# STM32C591 register map
File version: 2.1.0
CPU: CM33 r0p4, little endian, MPU, FPU, 4 interrupt priority bits
Registers are 32-bit, read-write, reset 0x0 unless marked. A register's access mark holds for its fields unless they carry their own. Offsets are from the block's base; [hi:lo] are bit positions; {n}, {i} and the like mark numbered series; 'fields as' and 'values as' point back to an identical list.

## RAMCFG — RAMCFG register block
Base 0x40026000
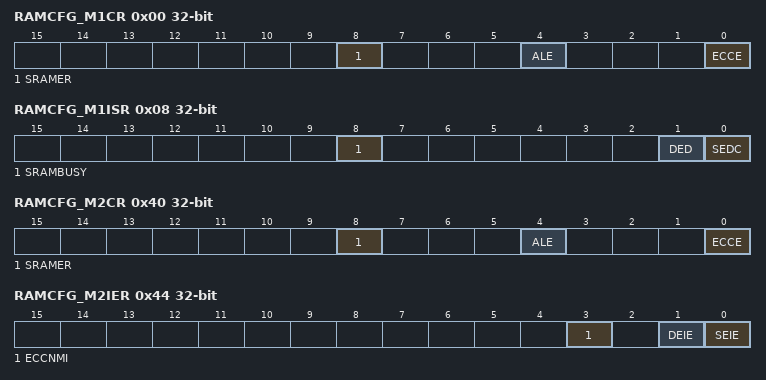
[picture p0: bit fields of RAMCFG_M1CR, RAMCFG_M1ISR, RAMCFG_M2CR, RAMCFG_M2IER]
0x00 RAMCFG_M1CR (reset mask 0xFFFFFFF0) — RAMCFG memory 1 control register
  [8] SRAMER — SRAM erase
    0=No erase operation ongoing; 1=Erase operation ongoing
  [4] ALE — Address latch enable
    0=Failing address not stored in the SRAMx ECC single/double error address registers; 1=Failing address stored in the SRAMx ECC single/double error address registers
  [0] ECCE — ECC enable.
    0=ECC disabled; 1=ECC enabled
0x08 RAMCFG_M1ISR ro — RAMCFG memory 1 interrupt status register
  [8] SRAMBUSY — SRAM busy with erase operation
    0=No erase operation ongoing; 1=Erase operation ongoing
  [1] DED — ECC double error detected
    0=No double error; 1=Double error detected
  [0] SEDC — ECC single error detected and corrected
    0=No single error; 1=Single error detected and corrected
0x28 RAMCFG_M1ERKEYR wo — RAMCFG memory 1 erase key register
  [7:0] ERASEKEY — Erase write protection key
0x40 RAMCFG_M2CR (reset mask 0xFFFFFFF0) — RAMCFG memory 2 control register
  fields as RAMCFG_M1CR
0x44 RAMCFG_M2IER — RAMCFG memory 2 interrupt enable register
  [3] ECCNMI — Double error NMI
    0=NMI not generated in case of ECC double error; 1=NMI generated in case of ECC double error
  [1] DEIE — ECC double error interrupt enable
    0=Double error interrupt disabled; 1=Double error interrupt enabled
  [0] SEIE — ECC single error interrupt enable
    0=Single error interrupt disabled; 1=Single error interrupt enabled
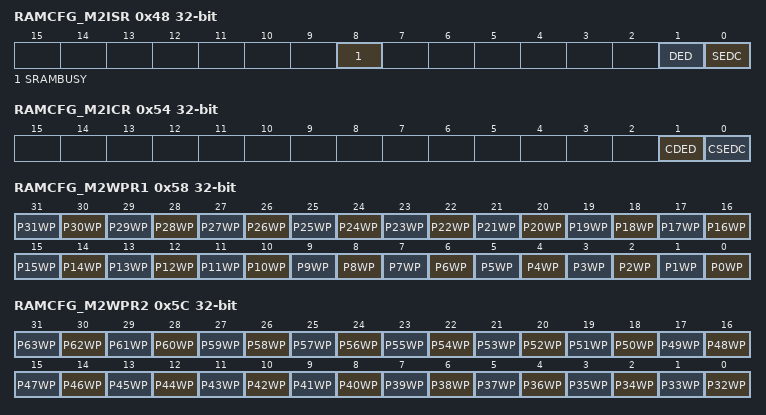
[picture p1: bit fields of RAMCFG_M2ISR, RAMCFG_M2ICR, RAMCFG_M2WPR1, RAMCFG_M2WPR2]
0x48 RAMCFG_M2ISR ro — RAMCFG memory 2 interrupt status register
  fields as RAMCFG_M1ISR
0x4C RAMCFG_M2SEAR ro — RAMCFG memory 2 ECC single error address register
  [31:0] ESEA — ECC single error address
0x50 RAMCFG_M2DEAR ro — RAMCFG memory 2 ECC double error address register
  [31:0] EDEA — ECC double error address
0x54 RAMCFG_M2ICR — RAMCFG memory 2 interrupt clear register
  [1] CDED — Clear ECC double error detected
  [0] CSEDC — Clear ECC single error detected and corrected
0x58 RAMCFG_M2WPR1 — RAMCFG memory 2 write protection register 1
  [all] fields
    0=Write protection of SRAM2 1-Kbyte page y is disabled; 1=Write protection of SRAM2 1-Kbyte page y is enabled
  [n] P{n}WP (n=0..31) — SRAM2 1-Kbyte page y write protection
0x5C RAMCFG_M2WPR2 — RAMCFG memory 2 write protection register 2
  [all] fields
    values as the fields of RAMCFG_M2WPR1
  [n-32] P{n}WP (n=32..63) — SRAM2 1-Kbyte page y write protection
0x64 RAMCFG_M2ECCKEYR wo — RAMCFG memory 2ECC key register
  [7:0] ECCKEY — ECC write protection key
0x68 RAMCFG_M2ERKEYR wo — RAMCFG memory 2 erase key register
  [7:0] ERASEKEY — Erase write protection key
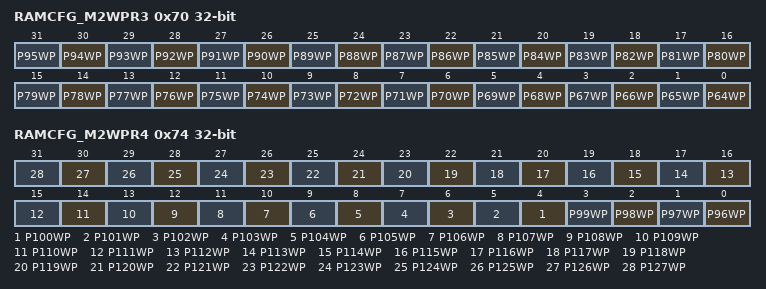
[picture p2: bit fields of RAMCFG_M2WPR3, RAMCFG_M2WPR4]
0x70 RAMCFG_M2WPR3 — RAMCFG memory 2 write protection register 3
  [all] fields
    values as the fields of RAMCFG_M2WPR1
  [n-64] P{n}WP (n=64..95) — SRAM2 1-Kbyte page y write protection
0x74 RAMCFG_M2WPR4 — RAMCFG memory 2 write protection register 4
  [all] fields
    values as the fields of RAMCFG_M2WPR1
  [n-96] P{n}WP (n=96..127) — SRAM2 1-Kbyte page y write protection

## TIM6 — TIM address block description
Base 0x40001000
Same registers: TIM7 0x40001400
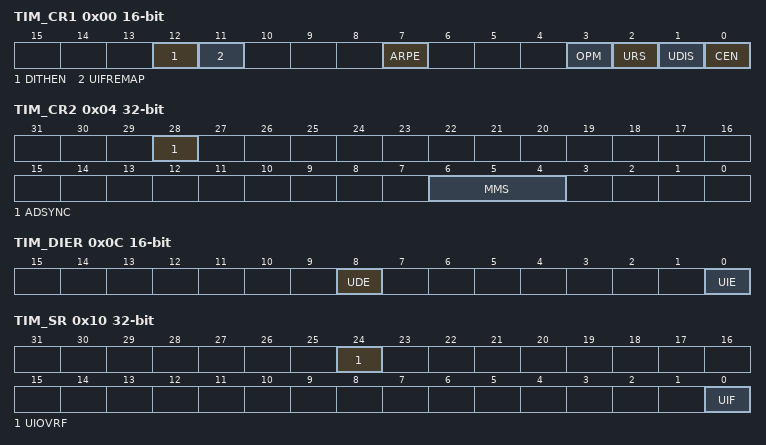
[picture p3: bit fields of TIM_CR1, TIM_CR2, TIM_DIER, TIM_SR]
0x00 TIM_CR1 16-bit — TIM control register 1
  [12] DITHEN — Dithering enable
    0=Dithering disabled; 1=Dithering enabled
  [11] UIFREMAP — UIF status bit remapping
    0=No remapping; 1=Remapping enabled
  [7] ARPE — Auto-reload preload enable
    0=TIMx_ARR register is not buffered; 1=TIMx_ARR register is buffered
  [3] OPM — One-pulse mode
    0=Counter is not stopped at update event; 1=Counter stops counting at the next update event (clearing the CEN bit)
  [2] URS — Update request source
    0=Any of the following events generates an update interrupt or DMA request if enabled; 1=Only counter overflow/underflow generates an update interrupt or DMA request if enabled
  [1] UDIS — Update disable
    0=UEV enabled; 1=UEV disabled
  [0] CEN — Counter enable
    0=Counter disabled; 1=Counter enabled
0x04 TIM_CR2 — TIM control register 2
  [28] ADSYNC — ADC synchronization
    0=The timer operates independently from the ADC; 1=The timer operation is synchronized with the ADC clock to provide jitter-free sampling point
  [6:4] MMS — Master mode selection
    0=Reset - the UG bit from the TIMx_EGR register is used as a trigger output (tim_trgo); 1=Enable - the Counter enable signal, tim_cnt_en, is used as a trigger output (tim_trgo); 2=Update - The update event is selected as a trigger output (tim_trgo)
0x0C TIM_DIER 16-bit — TIM DMA/Interrupt enable register
  [8] UDE — Update DMA request enable
    0=Update DMA request disabled; 1=Update DMA request enabled
  [0] UIE — Update interrupt enable
    0=Update interrupt disabled; 1=Update interrupt enabled
0x10 TIM_SR — TIM status register
  [24] UIOVRF — Update Interrupt Overrun flag
    0=No Update Interrupt Overrun; 1=Update Interrupt Overrun
  [0] UIF — Update interrupt flag
    0=No update occurred; 1=Update interrupt pending
0x14 TIM_EGR 16-bit — TIM event generation register
  [0] UG wo — Update generation
    0=No action; 1=Re-initializes the timer counter and generates an update of the registers
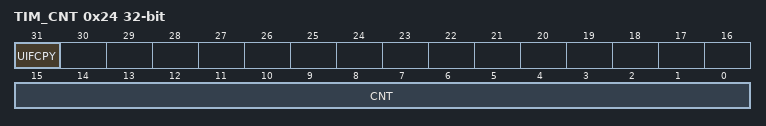
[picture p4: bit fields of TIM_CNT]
0x24 TIM_CNT — TIM counter
  [31] UIFCPY ro — UIF copy
  [15:0] CNT — Counter value
0x28 TIM_PSC 16-bit — TIM prescaler
  [15:0] PSC — Prescaler value
0x2C TIM_ARR reset 0xFFFF — TIM autoreload register
  [19:0] ARR — Auto-reload value

## USBSRAM — USBSRAM address block description
Base 0x40016400
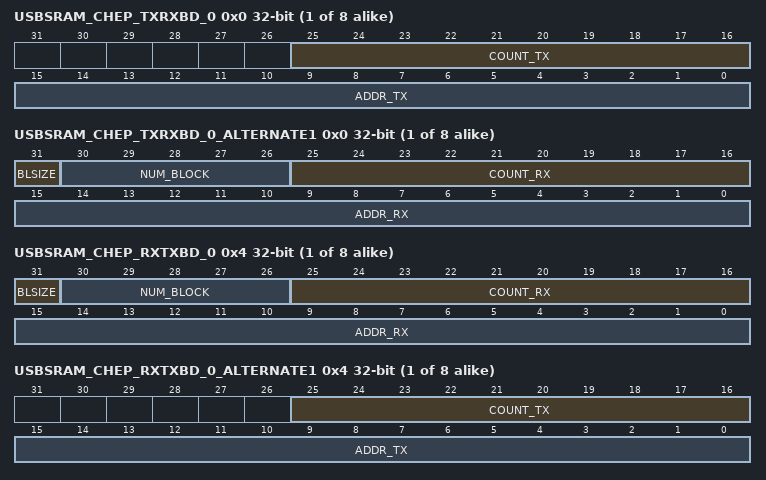
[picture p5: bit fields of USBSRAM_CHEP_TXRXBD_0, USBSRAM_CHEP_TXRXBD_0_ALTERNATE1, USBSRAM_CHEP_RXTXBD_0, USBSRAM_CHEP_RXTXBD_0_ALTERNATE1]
{0x0+8i} USBSRAM_CHEP_TXRXBD_{i} reset not defined (i=0..7) — Channel/endpoint transmit buffer descriptor {i}
  [25:16] COUNT_TX — Transmission byte count
  [15:0] ADDR_TX — Transmission buffer address
{0x0+8i} USBSRAM_CHEP_TXRXBD_{i}_ALTERNATE1 reset not defined (alternate view of USBSRAM_CHEP_TXRXBD_{i}) (i=0..7) — Channel/endpoint receive buffer descriptor {i}
  [31] BLSIZE — Block size
  [30:26] NUM_BLOCK — Number of blocks
  [25:16] COUNT_RX — Reception byte count
  [15:0] ADDR_RX — Reception buffer address
{0x4+8i} USBSRAM_CHEP_RXTXBD_{i} reset not defined (i=0..7) — Channel/endpoint receive buffer descriptor {i}
  fields as USBSRAM_CHEP_TXRXBD_0_ALTERNATE1
{0x4+8i} USBSRAM_CHEP_RXTXBD_{i}_ALTERNATE1 reset not defined (alternate view of USBSRAM_CHEP_RXTXBD_{i}) (i=0..7) — Channel/endpoint transmit buffer descriptor {i}
  fields as USBSRAM_CHEP_TXRXBD_0

## WWDG — WWDG address block description
Base 0x40002C00
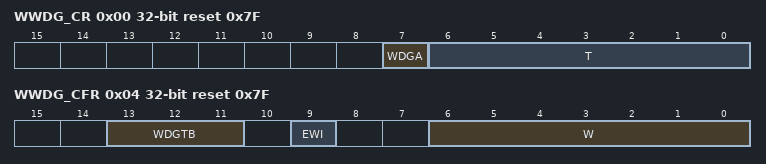
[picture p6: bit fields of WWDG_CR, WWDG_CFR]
0x00 WWDG_CR reset 0x7F — WWDG control register
  [7] WDGA — Activation bit
    0=Watchdog disabled; 1=Watchdog enabled
  [6:0] T — 7-bit counter (MSB to LSB)
0x04 WWDG_CFR reset 0x7F — WWDG configuration register
  [13:11] WDGTB — Timer base
    0=CK counter clock (PCLK div 4096) div 1; 1=CK counter clock (PCLK div 4096) div 2; 2=CK counter clock (PCLK div 4096) div 4; 3=CK counter clock (PCLK div 4096) div 8; 4=CK counter clock (PCLK div 4096) div 16; 5=CK counter clock (PCLK div 4096) div 32; 6=CK counter clock (PCLK div 4096) div 64; 7=CK counter clock (PCLK div 4096) div 128
  [9] EWI — Early wake-up interrupt enable
  [6:0] W — 7-bit window value
0x08 WWDG_SR — WWDG status register
  [0] EWIF — Early wake-up interrupt flag

## Notices in the file
Copyright (c) 2026 STMicroelectronics.
SPDX-License-Identifier: Apache-2.0
Licensed under the Apache License, Version 2.0 (the  License );
you may not use this file except in compliance with the License.
You may obtain a copy of the License at
http://www.apache.org/licenses/LICENSE-2.0
Unless required by applicable law or agreed to in writing, software
distributed under the License is distributed on an  AS IS  BASIS,
WITHOUT WARRANTIES OR CONDITIONS OF ANY KIND, either express or implied.
See the License for the specific language governing permissions and
limitations under the License.
